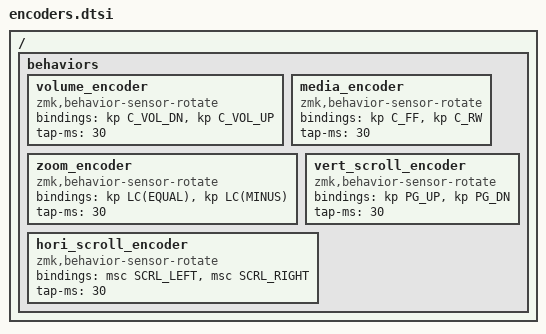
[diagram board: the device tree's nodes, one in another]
#define ZMK_MOUSE_DEFAULT_SCRL_VAL 50

#include <behaviors.dtsi>
#include <dt-bindings/zmk/mouse.h>

/ {
  behaviors {
    volume_encoder: volume_encoder {
      compatible = "zmk,behavior-sensor-rotate";
      #sensor-binding-cells = <0>;
      bindings = <&kp C_VOL_DN>, <&kp C_VOL_UP>;
      tap-ms = <30>;
    };

    media_encoder: media_encoder {
      compatible = "zmk,behavior-sensor-rotate";
      #sensor-binding-cells = <0>;
      bindings = <&kp C_FF>, <&kp C_RW>;
      tap-ms = <30>;
    };

    zoom_encoder: zoom_encoder {
      compatible = "zmk,behavior-sensor-rotate";
      #sensor-binding-cells = <0>;
      bindings = <&kp LC(EQUAL)>, <&kp LC(MINUS)>;
      tap-ms = <30>;
    };

    vert_scroll_encoder: vert_scroll_encoder {
      compatible = "zmk,behavior-sensor-rotate";
      #sensor-binding-cells = <0>;
      bindings = <&kp PG_UP>, <&kp PG_DN>;
      tap-ms = <30>;
    };

    hori_scroll_encoder: hori_scroll_encoder {
      compatible = "zmk,behavior-sensor-rotate";
      #sensor-binding-cells = <0>;
      bindings = <&msc SCRL_LEFT>, <&msc SCRL_RIGHT>;
      tap-ms = <30>;
    };
  };
};
